AUTOSAR XML (schema 4-0-3)
package /CalibrationComponents
  parameter sw component type THMR: data-type-mapping=THMR_CodeDataTypeMappingsSet
    provide port THMR_Pport: provided-interface=THMR_if
      provided-com-specs:
        init-value=15, parameter=KeTHMR_I_HeatingOverCurrt_Val
        init-value=20, parameter=KeTHMR_T_ACChrgCoolReqInletTempThld
        init-value=15, parameter=KeTHMR_T_AlwPreHeatTempDiffThld
        init-value=20, parameter=KeTHMR_T_DefaultReqInletTempThld
        init-value=33, parameter=KeTHMR_T_DrvCoolFlowRateMaxTempT10
        init-value=30, parameter=KeTHMR_T_DrvCoolFlowRateMaxTempT12
        init-value=38, parameter=KeTHMR_T_DrvCoolInletTempThld3
        init-value=20, parameter=KeTHMR_T_DrvCoolInletTempThld4
        init-value=33, parameter=KeTHMR_T_DrvCoolInletTempThld5
        init-value=20, parameter=KeTHMR_T_DrvCoolInletTempThld6
        init-value=18, parameter=KeTHMR_T_ForbidPreHeatTempDiffThld
        init-value=5, parameter=KeTHMR_T_InACBalanceDeltaCellTemp
        init-value=43, parameter=KeTHMR_T_InACChrgCoolTempThld
        init-value=0, parameter=KeTHMR_T_InACChrgPreHeatTempThld
        init-value=38, parameter=KeTHMR_T_InDriveCoolTempThld
        init-value=5, parameter=KeTHMR_T_InDrvBalanceDeltaCellTemp
        init-value=2, parameter=KeTHMR_T_OutACBalanceDeltaCellTemp
        init-value=38, parameter=KeTHMR_T_OutACChrgBalanceMaxCellTemp
        init-value=38, parameter=KeTHMR_T_OutACChrgCoolTempThld
        init-value=5, parameter=KeTHMR_T_OutACChrgPreHeatTempThld
        init-value=33, parameter=KeTHMR_T_OutDriveCoolTempThld
        init-value=2, parameter=KeTHMR_T_OutDrvBalanceDeltaCellTemp
        init-value=30, parameter=KeTHMR_T_OutDrvBalanceMaxCellTemp
        init-value=0, parameter=KeTHMR_T_TargetInletWaterTemp_Val
        init-value=15, parameter=KeTHMR_T_TempRiseFastFlt_Val
        init-value=10, parameter=KeTHMR_T_TempRiseFastRelease_Val
        init-value=1, parameter=KeTHMR_T_TempRiseSlowFlt_Val
        init-value=1, parameter=KeTHMR_T_TempRiseSlowRelease_Val
        init-value=1, parameter=KeTHMR_T_WaterTempChangeRateReq
        init-value=0, parameter=KeTHMR_T_WaterTempChangeRateReq_Val
        init-value=0, parameter=KeTHMR_T_WaterTempChangeRateReset
        init-value=1000, parameter=KeTHMR_kP_PackHeatPowerFactor
        init-value=0, parameter=KeTHMR_kP_PackHeatPowerReq_Val
        init-value=0, parameter=KeTHMR_kP_PackHeatPowerReset
        init-value=1, parameter=KeTHMR_t_ACChrgCoolOffThld
        init-value=0.5, parameter=KeTHMR_t_ACChrgCoolOff_Ts
        init-value=2, parameter=KeTHMR_t_ACChrgCoolOnThld
        init-value=0.5, parameter=KeTHMR_t_ACChrgCoolOn_Ts
        init-value=1, parameter=KeTHMR_t_ACChrgHeatOffThld
        init-value=0.5, parameter=KeTHMR_t_ACChrgHeatOff_Ts
        init-value=2, parameter=KeTHMR_t_ACChrgHeatOnThld
        init-value=0.5, parameter=KeTHMR_t_ACChrgHeatOn_Ts
        init-value=1, parameter=KeTHMR_t_BHeatCloseDeb
        init-value=1, parameter=KeTHMR_t_DriveCoolOffThld
        init-value=0.5, parameter=KeTHMR_t_DriveCoolOff_Ts
        init-value=2, parameter=KeTHMR_t_DriveCoolOnThld
        init-value=0.5, parameter=KeTHMR_t_DriveCoolOn_Ts
        init-value=1, parameter=KeTHMR_t_HeatingOverCurrtTime_Val
        init-value=0.10000000149011612, parameter=KeTHMR_t_HeatingOverCurrt_Ts
        init-value=1, parameter=KeTHMR_t_InletWaterTempFltSet_Val
        init-value=10, parameter=KeTHMR_t_InletWaterTempRelease_Val
        init-value=600, parameter=KeTHMR_t_InletWaterTempTime_Val
        init-value=0.10000000149011612, parameter=KeTHMR_t_InletWaterTemp_Ts
        init-value=900, parameter=KeTHMR_t_TempOver_Ts
        init-value=900, parameter=KeTHMR_t_TempRelease_Ts
        init-value=300, parameter=KeTHMR_t_TempSlowOver_Ts
        init-value=300, parameter=KeTHMR_t_TempSlowRelease_Ts
        init-value=0.10000000149011612, parameter=KeTHMR_t_Temp_Ts
        init-value=0, parameter=KeTHMR_b_BatteryCooling_flt_En
        init-value=1, parameter=KeTHMR_b_HeatReqFromCHMR
        init-value=0, parameter=KeTHMR_b_HeatTempRiseFast_flt_En
        init-value=0, parameter=KeTHMR_b_HeatTempRiseSlow_flt_En
        init-value=0, parameter=KeTHMR_b_HeatingOverCurrt_flt_En
        init-value=0, parameter=KeTHMR_b_PackHeatPowerReq_En
        init-value=0, parameter=KeTHMR_b_PackHeatReq_En
        init-value=0, parameter=KeTHMR_b_PreHeatSwitchDefaultVal
        init-value=0, parameter=KeTHMR_b_TargetInletWaterTemp_En
        init-value=0, parameter=KeTHMR_b_ThermalFlowRateReq_En
        init-value=0, parameter=KeTHMR_b_ThermalManageReq_En
        init-value=0, parameter=KeTHMR_b_WaterTempChangeRateReq_En
        init-value=10, parameter=KeTHMR_k_ACChrgBalanceFlowRateReqVal
        init-value=12, parameter=KeTHMR_k_ACChrgCoolFlowRateReqV4
        init-value=0, parameter=KeTHMR_k_BatteryCooling_flt_Val
        init-value=10, parameter=KeTHMR_k_DefaultFlowRateReqThld
        init-value=12, parameter=KeTHMR_k_DrvCoolFlowRateReqV1
        init-value=12, parameter=KeTHMR_k_DrvCoolFlowRateReqV2
        init-value=10, parameter=KeTHMR_k_DrvCoolFlowRateReqV3
        init-value=0, parameter=KeTHMR_k_HeatTempRiseFast_flt_Val
        init-value=0, parameter=KeTHMR_k_HeatTempRiseSlow_flt_Val
        init-value=0, parameter=KeTHMR_k_HeatingOverCurrt_flt_Val
        init-value=2, parameter=KeTHMR_k_NumberOfWaterThermistors
        init-value=0, parameter=KeTHMR_k_PackHeatReq_Val
        init-value=16, parameter=KeTHMR_k_TempNumber
        init-value=0, parameter=KeTHMR_k_ThermalFlowRateReq_Val
        init-value=0, parameter=KeTHMR_k_ThermalManageReq_Val
package /THMR_Code_pkg/THMR_Code_swc
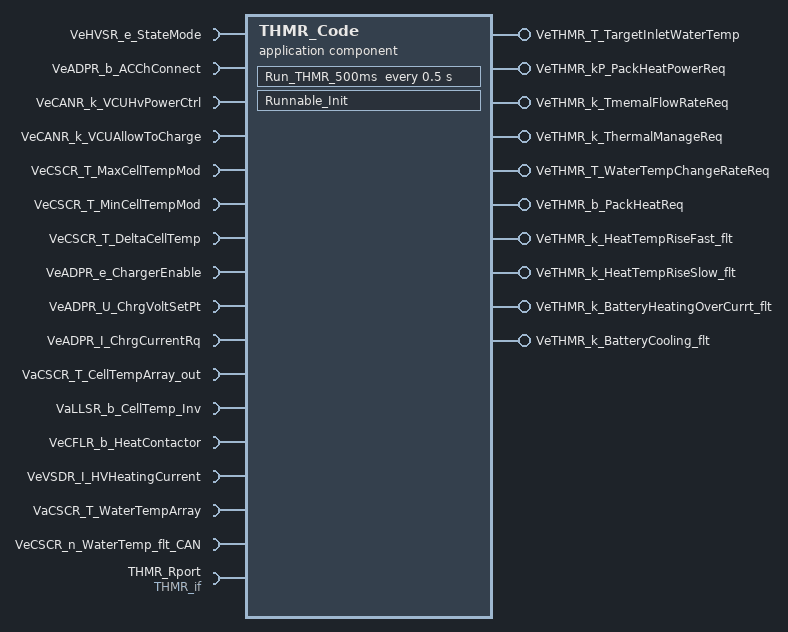
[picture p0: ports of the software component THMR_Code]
  application sw component type THMR_Code
    16 x require port:
      VeHVSR_e_StateMode: nonqueued-receiver-com-spec{data-element=VeHVSR_e_StateMode, init-value=CeHVSR_e_StateModeReserved}, required-interface=VeHVSR_e_StateMode
      VeADPR_b_ACChConnect: nonqueued-receiver-com-spec{data-element=VeADPR_b_ACChConnect, init-value=0}, required-interface=VeADPR_b_ACChConnect
      VeCANR_k_VCUHvPowerCtrl: nonqueued-receiver-com-spec{data-element=VeCANR_k_VCUHvPowerCtrl, init-value=0}, required-interface=VeCANR_k_VCUHvPowerCtrl
      VeCANR_k_VCUAllowToCharge: nonqueued-receiver-com-spec{data-element=VeCANR_k_VCUAllowToCharge, init-value=0}, required-interface=VeCANR_k_VCUAllowToCharge
      VeCSCR_T_MaxCellTempMod: nonqueued-receiver-com-spec{data-element=VeCSCR_T_MaxCellTempMod, init-value=0}, required-interface=VeCSCR_T_MaxCellTempMod
      VeCSCR_T_MinCellTempMod: nonqueued-receiver-com-spec{data-element=VeCSCR_T_MinCellTempMod, init-value=0}, required-interface=VeCSCR_T_MinCellTempMod
      VeCSCR_T_DeltaCellTemp: nonqueued-receiver-com-spec{data-element=VeCSCR_T_DeltaCellTemp, init-value=0}, required-interface=VeCSCR_T_DeltaCellTemp
      VeADPR_e_ChargerEnable: nonqueued-receiver-com-spec{data-element=VeADPR_e_ChargerEnable, init-value=CeCHMR_e_OBC_ChrgEnblDefault}, required-interface=VeADPR_e_ChargerEnable
      VeADPR_U_ChrgVoltSetPt: nonqueued-receiver-com-spec{data-element=VeADPR_U_ChrgVoltSetPt, init-value=0}, required-interface=VeADPR_U_ChrgVoltSetPt
      VeADPR_I_ChrgCurrentRq: nonqueued-receiver-com-spec{data-element=VeADPR_I_ChrgCurrentRq, init-value=0}, required-interface=VeADPR_I_ChrgCurrentRq
      VaCSCR_T_CellTempArray_out: nonqueued-receiver-com-spec{data-element=VaCSCR_T_CellTempArray_out, init-value=16 x 0}, required-interface=VaCSCR_T_CellTempArray_out
      VaLLSR_b_CellTemp_Inv: nonqueued-receiver-com-spec{data-element=VaLLSR_b_CellTemp_Inv, init-value=16 x 0}, required-interface=VaLLSR_b_CellTemp_Inv
      VeCFLR_b_HeatContactor: nonqueued-receiver-com-spec{data-element=VeCFLR_b_HeatContactor, init-value=0}, required-interface=VeCFLR_b_HeatContactor
      VeVSDR_I_HVHeatingCurrent: nonqueued-receiver-com-spec{data-element=VeVSDR_I_HVHeatingCurrent, init-value=0}, required-interface=VeVSDR_I_HVHeatingCurrent
      VaCSCR_T_WaterTempArray: nonqueued-receiver-com-spec{data-element=VaCSCR_T_WaterTempArray, init-value=[0, 0]}, required-interface=VaCSCR_T_WaterTempArray
      VeCSCR_n_WaterTemp_flt_CAN: nonqueued-receiver-com-spec{data-element=VeCSCR_n_WaterTemp_flt_CAN, init-value=0}, required-interface=VeCSCR_n_WaterTemp_flt_CAN
    10 x provide port:
      VeTHMR_T_TargetInletWaterTemp: nonqueued-sender-com-spec{data-element=VeTHMR_T_TargetInletWaterTemp, init-value=0}, provided-interface=VeTHMR_T_TargetInletWaterTemp
      VeTHMR_kP_PackHeatPowerReq: nonqueued-sender-com-spec{data-element=VeTHMR_kP_PackHeatPowerReq, init-value=0}, provided-interface=VeTHMR_kP_PackHeatPowerReq
      VeTHMR_k_TmemalFlowRateReq: nonqueued-sender-com-spec{data-element=VeTHMR_k_TmemalFlowRateReq, init-value=0}, provided-interface=VeTHMR_k_TmemalFlowRateReq
      VeTHMR_k_ThermalManageReq: nonqueued-sender-com-spec{data-element=VeTHMR_k_ThermalManageReq, init-value=0}, provided-interface=VeTHMR_k_ThermalManageReq
      VeTHMR_T_WaterTempChangeRateReq: nonqueued-sender-com-spec{data-element=VeTHMR_T_WaterTempChangeRateReq, init-value=0}, provided-interface=VeTHMR_T_WaterTempChangeRateReq
      VeTHMR_b_PackHeatReq: nonqueued-sender-com-spec{data-element=VeTHMR_b_PackHeatReq, init-value=0}, provided-interface=VeTHMR_b_PackHeatReq
      VeTHMR_k_HeatTempRiseFast_flt: nonqueued-sender-com-spec{data-element=VeTHMR_k_HeatTempRiseFast_flt, init-value=0}, provided-interface=VeTHMR_k_HeatTempRiseFast_flt
      VeTHMR_k_HeatTempRiseSlow_flt: nonqueued-sender-com-spec{data-element=VeTHMR_k_HeatTempRiseSlow_flt, init-value=0}, provided-interface=VeTHMR_k_HeatTempRiseSlow_flt
      VeTHMR_k_BatteryHeatingOverCurrt_flt: nonqueued-sender-com-spec{data-element=VeTHMR_k_BatteryHeatingOverCurrt_flt, init-value=0}, provided-interface=VeTHMR_k_BatteryHeatingOverCurrt_flt
      VeTHMR_k_BatteryCooling_flt: nonqueued-sender-com-spec{data-element=VeTHMR_k_BatteryCooling_flt, init-value=0}, provided-interface=VeTHMR_k_BatteryCooling_flt
    require port THMR_Rport: required-interface=THMR_if
    behavior THMR_Code: data-type-mapping=THMR_CodeDataTypeMappingsSet, handle-termination-and-restart=NO-SUPPORT
      timing event Event_Run_THMR_500ms: start-on-event=Run_THMR_500ms, period=0.5
      runnable Runnable_Init: symbol=THMR_Code_Init
      runnable Run_THMR_500ms
        data-read-access:
          16 x access:
            IN_VaCSCR_T_CellTempArray_out_VaCSCR_T_CellTempArray_out: accessed-variable=VaCSCR_T_CellTempArray_out.VaCSCR_T_CellTempArray_out
            IN_VaCSCR_T_WaterTempArray_VaCSCR_T_WaterTempArray: accessed-variable=VaCSCR_T_WaterTempArray.VaCSCR_T_WaterTempArray
            IN_VaLLSR_b_CellTemp_Inv_VaLLSR_b_CellTemp_Inv: accessed-variable=VaLLSR_b_CellTemp_Inv.VaLLSR_b_CellTemp_Inv
            IN_VeADPR_I_ChrgCurrentRq_VeADPR_I_ChrgCurrentRq: accessed-variable=VeADPR_I_ChrgCurrentRq.VeADPR_I_ChrgCurrentRq
            IN_VeADPR_U_ChrgVoltSetPt_VeADPR_U_ChrgVoltSetPt: accessed-variable=VeADPR_U_ChrgVoltSetPt.VeADPR_U_ChrgVoltSetPt
            IN_VeADPR_b_ACChConnect_VeADPR_b_ACChConnect: accessed-variable=VeADPR_b_ACChConnect.VeADPR_b_ACChConnect
            IN_VeADPR_e_ChargerEnable_VeADPR_e_ChargerEnable: accessed-variable=VeADPR_e_ChargerEnable.VeADPR_e_ChargerEnable
            IN_VeCANR_k_VCUAllowToCharge_VeCANR_k_VCUAllowToCharge: accessed-variable=VeCANR_k_VCUAllowToCharge.VeCANR_k_VCUAllowToCharge
            IN_VeCANR_k_VCUHvPowerCtrl_VeCANR_k_VCUHvPowerCtrl: accessed-variable=VeCANR_k_VCUHvPowerCtrl.VeCANR_k_VCUHvPowerCtrl
            IN_VeCFLR_b_HeatContactor_VeCFLR_b_HeatContactor: accessed-variable=VeCFLR_b_HeatContactor.VeCFLR_b_HeatContactor
            IN_VeCSCR_T_DeltaCellTemp_VeCSCR_T_DeltaCellTemp: accessed-variable=VeCSCR_T_DeltaCellTemp.VeCSCR_T_DeltaCellTemp
            IN_VeCSCR_T_MaxCellTempMod_VeCSCR_T_MaxCellTempMod: accessed-variable=VeCSCR_T_MaxCellTempMod.VeCSCR_T_MaxCellTempMod
            IN_VeCSCR_T_MinCellTempMod_VeCSCR_T_MinCellTempMod: accessed-variable=VeCSCR_T_MinCellTempMod.VeCSCR_T_MinCellTempMod
            IN_VeCSCR_n_WaterTemp_flt_CAN_VeCSCR_n_WaterTemp_flt_CAN: accessed-variable=VeCSCR_n_WaterTemp_flt_CAN.VeCSCR_n_WaterTemp_flt_CAN
            IN_VeHVSR_e_StateMode_VeHVSR_e_StateMode: accessed-variable=VeHVSR_e_StateMode.VeHVSR_e_StateMode
            IN_VeVSDR_I_HVHeatingCurrent_VeVSDR_I_HVHeatingCurrent: accessed-variable=VeVSDR_I_HVHeatingCurrent.VeVSDR_I_HVHeatingCurrent
        data-send-points:
          10 x access:
            OUT_VeTHMR_T_TargetInletWaterTemp_VeTHMR_T_Ta_c8198ff3ffec4d8f: accessed-variable=VeTHMR_T_TargetInletWaterTemp.VeTHMR_T_TargetInletWaterTemp
            OUT_VeTHMR_kP_PackHeatPowerReq_VeTHMR_kP_PackHeatPowerReq: accessed-variable=VeTHMR_kP_PackHeatPowerReq.VeTHMR_kP_PackHeatPowerReq
            OUT_VeTHMR_k_TmemalFlowRateReq_VeTHMR_k_TmemalFlowRateReq: accessed-variable=VeTHMR_k_TmemalFlowRateReq.VeTHMR_k_TmemalFlowRateReq
            OUT_VeTHMR_k_ThermalManageReq_VeTHMR_k_ThermalManageReq: accessed-variable=VeTHMR_k_ThermalManageReq.VeTHMR_k_ThermalManageReq
            OUT_VeTHMR_T_WaterTempChangeRateReq_VeTHMR_T_2941e6b012148f41: accessed-variable=VeTHMR_T_WaterTempChangeRateReq.VeTHMR_T_WaterTempChangeRateReq
            OUT_VeTHMR_b_PackHeatReq_VeTHMR_b_PackHeatReq: accessed-variable=VeTHMR_b_PackHeatReq.VeTHMR_b_PackHeatReq
            OUT_VeTHMR_k_HeatTempRiseFast_flt_VeTHMR_k_He_028bcb15faa38c93: accessed-variable=VeTHMR_k_HeatTempRiseFast_flt.VeTHMR_k_HeatTempRiseFast_flt
            OUT_VeTHMR_k_HeatTempRiseSlow_flt_VeTHMR_k_He_8dcb84f5eb5cce9f: accessed-variable=VeTHMR_k_HeatTempRiseSlow_flt.VeTHMR_k_HeatTempRiseSlow_flt
            OUT_VeTHMR_k_BatteryHeatingOverCurrt_flt_VeTH_4f2e52cb085c64db: accessed-variable=VeTHMR_k_BatteryHeatingOverCurrt_flt.VeTHMR_k_BatteryHeatingOverCurrt_flt
            OUT_VeTHMR_k_BatteryCooling_flt_VeTHMR_k_BatteryCooling_flt: accessed-variable=VeTHMR_k_BatteryCooling_flt.VeTHMR_k_BatteryCooling_flt
        85 x parameter access:
          CALPRM_THMR_Rport_KeTHMR_I_HeatingOverCurrt_Val: accessed-parameter=THMR_Rport.KeTHMR_I_HeatingOverCurrt_Val
          CALPRM_THMR_Rport_KeTHMR_T_ACChrgCoolReqInletTempThld: accessed-parameter=THMR_Rport.KeTHMR_T_ACChrgCoolReqInletTempThld
          CALPRM_THMR_Rport_KeTHMR_T_AlwPreHeatTempDiffThld: accessed-parameter=THMR_Rport.KeTHMR_T_AlwPreHeatTempDiffThld
          CALPRM_THMR_Rport_KeTHMR_T_DefaultReqInletTempThld: accessed-parameter=THMR_Rport.KeTHMR_T_DefaultReqInletTempThld
          CALPRM_THMR_Rport_KeTHMR_T_DrvCoolFlowRateMaxTempT10: accessed-parameter=THMR_Rport.KeTHMR_T_DrvCoolFlowRateMaxTempT10
          CALPRM_THMR_Rport_KeTHMR_T_DrvCoolFlowRateMaxTempT12: accessed-parameter=THMR_Rport.KeTHMR_T_DrvCoolFlowRateMaxTempT12
          CALPRM_THMR_Rport_KeTHMR_T_DrvCoolInletTempThld{3..6}: accessed-parameter=THMR_Rport.KeTHMR_T_DrvCoolInletTempThld{3..6}
          CALPRM_THMR_Rport_KeTHMR_T_ForbidPreHeatTempDiffThld: accessed-parameter=THMR_Rport.KeTHMR_T_ForbidPreHeatTempDiffThld
          CALPRM_THMR_Rport_KeTHMR_T_InACBalanceDeltaCellTemp: accessed-parameter=THMR_Rport.KeTHMR_T_InACBalanceDeltaCellTemp
          CALPRM_THMR_Rport_KeTHMR_T_InACChrgCoolTempThld: accessed-parameter=THMR_Rport.KeTHMR_T_InACChrgCoolTempThld
          CALPRM_THMR_Rport_KeTHMR_T_InACChrgPreHeatTempThld: accessed-parameter=THMR_Rport.KeTHMR_T_InACChrgPreHeatTempThld
          CALPRM_THMR_Rport_KeTHMR_T_InDriveCoolTempThld: accessed-parameter=THMR_Rport.KeTHMR_T_InDriveCoolTempThld
          CALPRM_THMR_Rport_KeTHMR_T_InDrvBalanceDeltaCellTemp: accessed-parameter=THMR_Rport.KeTHMR_T_InDrvBalanceDeltaCellTemp
          CALPRM_THMR_Rport_KeTHMR_T_OutACBalanceDeltaCellTemp: accessed-parameter=THMR_Rport.KeTHMR_T_OutACBalanceDeltaCellTemp
          CALPRM_THMR_Rport_KeTHMR_T_OutACChrgBalanceMaxCellTemp: accessed-parameter=THMR_Rport.KeTHMR_T_OutACChrgBalanceMaxCellTemp
          CALPRM_THMR_Rport_KeTHMR_T_OutACChrgCoolTempThld: accessed-parameter=THMR_Rport.KeTHMR_T_OutACChrgCoolTempThld
          CALPRM_THMR_Rport_KeTHMR_T_OutACChrgPreHeatTempThld: accessed-parameter=THMR_Rport.KeTHMR_T_OutACChrgPreHeatTempThld
          CALPRM_THMR_Rport_KeTHMR_T_OutDriveCoolTempThld: accessed-parameter=THMR_Rport.KeTHMR_T_OutDriveCoolTempThld
          CALPRM_THMR_Rport_KeTHMR_T_OutDrvBalanceDeltaCellTemp: accessed-parameter=THMR_Rport.KeTHMR_T_OutDrvBalanceDeltaCellTemp
          CALPRM_THMR_Rport_KeTHMR_T_OutDrvBalanceMaxCellTemp: accessed-parameter=THMR_Rport.KeTHMR_T_OutDrvBalanceMaxCellTemp
          CALPRM_THMR_Rport_KeTHMR_T_TargetInletWaterTemp_Val: accessed-parameter=THMR_Rport.KeTHMR_T_TargetInletWaterTemp_Val
          CALPRM_THMR_Rport_KeTHMR_T_TempRiseFastFlt_Val: accessed-parameter=THMR_Rport.KeTHMR_T_TempRiseFastFlt_Val
          CALPRM_THMR_Rport_KeTHMR_T_TempRiseFastRelease_Val: accessed-parameter=THMR_Rport.KeTHMR_T_TempRiseFastRelease_Val
          CALPRM_THMR_Rport_KeTHMR_T_TempRiseSlowFlt_Val: accessed-parameter=THMR_Rport.KeTHMR_T_TempRiseSlowFlt_Val
          CALPRM_THMR_Rport_KeTHMR_T_TempRiseSlowRelease_Val: accessed-parameter=THMR_Rport.KeTHMR_T_TempRiseSlowRelease_Val
          CALPRM_THMR_Rport_KeTHMR_T_WaterTempChangeRateReq: accessed-parameter=THMR_Rport.KeTHMR_T_WaterTempChangeRateReq
          CALPRM_THMR_Rport_KeTHMR_T_WaterTempChangeRateReq_Val: accessed-parameter=THMR_Rport.KeTHMR_T_WaterTempChangeRateReq_Val
          CALPRM_THMR_Rport_KeTHMR_T_WaterTempChangeRateReset: accessed-parameter=THMR_Rport.KeTHMR_T_WaterTempChangeRateReset
          CALPRM_THMR_Rport_KeTHMR_b_BatteryCooling_flt_En: accessed-parameter=THMR_Rport.KeTHMR_b_BatteryCooling_flt_En
          CALPRM_THMR_Rport_KeTHMR_b_HeatReqFromCHMR: accessed-parameter=THMR_Rport.KeTHMR_b_HeatReqFromCHMR
          CALPRM_THMR_Rport_KeTHMR_b_HeatTempRiseFast_flt_En: accessed-parameter=THMR_Rport.KeTHMR_b_HeatTempRiseFast_flt_En
          CALPRM_THMR_Rport_KeTHMR_b_HeatTempRiseSlow_flt_En: accessed-parameter=THMR_Rport.KeTHMR_b_HeatTempRiseSlow_flt_En
          CALPRM_THMR_Rport_KeTHMR_b_HeatingOverCurrt_flt_En: accessed-parameter=THMR_Rport.KeTHMR_b_HeatingOverCurrt_flt_En
          CALPRM_THMR_Rport_KeTHMR_b_PackHeatPowerReq_En: accessed-parameter=THMR_Rport.KeTHMR_b_PackHeatPowerReq_En
          CALPRM_THMR_Rport_KeTHMR_b_PackHeatReq_En: accessed-parameter=THMR_Rport.KeTHMR_b_PackHeatReq_En
          CALPRM_THMR_Rport_KeTHMR_b_PreHeatSwitchDefaultVal: accessed-parameter=THMR_Rport.KeTHMR_b_PreHeatSwitchDefaultVal
          CALPRM_THMR_Rport_KeTHMR_b_TargetInletWaterTemp_En: accessed-parameter=THMR_Rport.KeTHMR_b_TargetInletWaterTemp_En
          CALPRM_THMR_Rport_KeTHMR_b_ThermalFlowRateReq_En: accessed-parameter=THMR_Rport.KeTHMR_b_ThermalFlowRateReq_En
          CALPRM_THMR_Rport_KeTHMR_b_ThermalManageReq_En: accessed-parameter=THMR_Rport.KeTHMR_b_ThermalManageReq_En
          CALPRM_THMR_Rport_KeTHMR_b_WaterTempChangeRateReq_En: accessed-parameter=THMR_Rport.KeTHMR_b_WaterTempChangeRateReq_En
          CALPRM_THMR_Rport_KeTHMR_kP_PackHeatPowerFactor: accessed-parameter=THMR_Rport.KeTHMR_kP_PackHeatPowerFactor
          CALPRM_THMR_Rport_KeTHMR_kP_PackHeatPowerReq_Val: accessed-parameter=THMR_Rport.KeTHMR_kP_PackHeatPowerReq_Val
          CALPRM_THMR_Rport_KeTHMR_kP_PackHeatPowerReset: accessed-parameter=THMR_Rport.KeTHMR_kP_PackHeatPowerReset
          CALPRM_THMR_Rport_KeTHMR_k_ACChrgBalanceFlowRateReqVal: accessed-parameter=THMR_Rport.KeTHMR_k_ACChrgBalanceFlowRateReqVal
          CALPRM_THMR_Rport_KeTHMR_k_ACChrgCoolFlowRateReqV4: accessed-parameter=THMR_Rport.KeTHMR_k_ACChrgCoolFlowRateReqV4
          CALPRM_THMR_Rport_KeTHMR_k_BatteryCooling_flt_Val: accessed-parameter=THMR_Rport.KeTHMR_k_BatteryCooling_flt_Val
          CALPRM_THMR_Rport_KeTHMR_k_DefaultFlowRateReqThld: accessed-parameter=THMR_Rport.KeTHMR_k_DefaultFlowRateReqThld
          CALPRM_THMR_Rport_KeTHMR_k_DrvCoolFlowRateReqV{1..3}: accessed-parameter=THMR_Rport.KeTHMR_k_DrvCoolFlowRateReqV{1..3}
          CALPRM_THMR_Rport_KeTHMR_k_HeatTempRiseFast_flt_Val: accessed-parameter=THMR_Rport.KeTHMR_k_HeatTempRiseFast_flt_Val
          CALPRM_THMR_Rport_KeTHMR_k_HeatTempRiseSlow_flt_Val: accessed-parameter=THMR_Rport.KeTHMR_k_HeatTempRiseSlow_flt_Val
          CALPRM_THMR_Rport_KeTHMR_k_HeatingOverCurrt_flt_Val: accessed-parameter=THMR_Rport.KeTHMR_k_HeatingOverCurrt_flt_Val
          CALPRM_THMR_Rport_KeTHMR_k_NumberOfWaterThermistors: accessed-parameter=THMR_Rport.KeTHMR_k_NumberOfWaterThermistors
          CALPRM_THMR_Rport_KeTHMR_k_PackHeatReq_Val: accessed-parameter=THMR_Rport.KeTHMR_k_PackHeatReq_Val
          CALPRM_THMR_Rport_KeTHMR_k_TempNumber: accessed-parameter=THMR_Rport.KeTHMR_k_TempNumber
          CALPRM_THMR_Rport_KeTHMR_k_ThermalFlowRateReq_Val: accessed-parameter=THMR_Rport.KeTHMR_k_ThermalFlowRateReq_Val
          CALPRM_THMR_Rport_KeTHMR_k_ThermalManageReq_Val: accessed-parameter=THMR_Rport.KeTHMR_k_ThermalManageReq_Val
          CALPRM_THMR_Rport_KeTHMR_t_ACChrgCoolOffThld: accessed-parameter=THMR_Rport.KeTHMR_t_ACChrgCoolOffThld
          CALPRM_THMR_Rport_KeTHMR_t_ACChrgCoolOff_Ts: accessed-parameter=THMR_Rport.KeTHMR_t_ACChrgCoolOff_Ts
          CALPRM_THMR_Rport_KeTHMR_t_ACChrgCoolOnThld: accessed-parameter=THMR_Rport.KeTHMR_t_ACChrgCoolOnThld
          CALPRM_THMR_Rport_KeTHMR_t_ACChrgCoolOn_Ts: accessed-parameter=THMR_Rport.KeTHMR_t_ACChrgCoolOn_Ts
          CALPRM_THMR_Rport_KeTHMR_t_ACChrgHeatOffThld: accessed-parameter=THMR_Rport.KeTHMR_t_ACChrgHeatOffThld
          CALPRM_THMR_Rport_KeTHMR_t_ACChrgHeatOff_Ts: accessed-parameter=THMR_Rport.KeTHMR_t_ACChrgHeatOff_Ts
          CALPRM_THMR_Rport_KeTHMR_t_ACChrgHeatOnThld: accessed-parameter=THMR_Rport.KeTHMR_t_ACChrgHeatOnThld
          CALPRM_THMR_Rport_KeTHMR_t_ACChrgHeatOn_Ts: accessed-parameter=THMR_Rport.KeTHMR_t_ACChrgHeatOn_Ts
          CALPRM_THMR_Rport_KeTHMR_t_BHeatCloseDeb: accessed-parameter=THMR_Rport.KeTHMR_t_BHeatCloseDeb
          CALPRM_THMR_Rport_KeTHMR_t_DriveCoolOffThld: accessed-parameter=THMR_Rport.KeTHMR_t_DriveCoolOffThld
          CALPRM_THMR_Rport_KeTHMR_t_DriveCoolOff_Ts: accessed-parameter=THMR_Rport.KeTHMR_t_DriveCoolOff_Ts
          CALPRM_THMR_Rport_KeTHMR_t_DriveCoolOnThld: accessed-parameter=THMR_Rport.KeTHMR_t_DriveCoolOnThld
          CALPRM_THMR_Rport_KeTHMR_t_DriveCoolOn_Ts: accessed-parameter=THMR_Rport.KeTHMR_t_DriveCoolOn_Ts
          CALPRM_THMR_Rport_KeTHMR_t_HeatingOverCurrtTime_Val: accessed-parameter=THMR_Rport.KeTHMR_t_HeatingOverCurrtTime_Val
          CALPRM_THMR_Rport_KeTHMR_t_HeatingOverCurrt_Ts: accessed-parameter=THMR_Rport.KeTHMR_t_HeatingOverCurrt_Ts
          CALPRM_THMR_Rport_KeTHMR_t_InletWaterTempFltSet_Val: accessed-parameter=THMR_Rport.KeTHMR_t_InletWaterTempFltSet_Val
          CALPRM_THMR_Rport_KeTHMR_t_InletWaterTempRelease_Val: accessed-parameter=THMR_Rport.KeTHMR_t_InletWaterTempRelease_Val
          CALPRM_THMR_Rport_KeTHMR_t_InletWaterTempTime_Val: accessed-parameter=THMR_Rport.KeTHMR_t_InletWaterTempTime_Val
          CALPRM_THMR_Rport_KeTHMR_t_InletWaterTemp_Ts: accessed-parameter=THMR_Rport.KeTHMR_t_InletWaterTemp_Ts
          CALPRM_THMR_Rport_KeTHMR_t_TempOver_Ts: accessed-parameter=THMR_Rport.KeTHMR_t_TempOver_Ts
          CALPRM_THMR_Rport_KeTHMR_t_TempRelease_Ts: accessed-parameter=THMR_Rport.KeTHMR_t_TempRelease_Ts
          CALPRM_THMR_Rport_KeTHMR_t_TempSlowOver_Ts: accessed-parameter=THMR_Rport.KeTHMR_t_TempSlowOver_Ts
          CALPRM_THMR_Rport_KeTHMR_t_TempSlowRelease_Ts: accessed-parameter=THMR_Rport.KeTHMR_t_TempSlowRelease_Ts
          CALPRM_THMR_Rport_KeTHMR_t_Temp_Ts: accessed-parameter=THMR_Rport.KeTHMR_t_Temp_Ts
